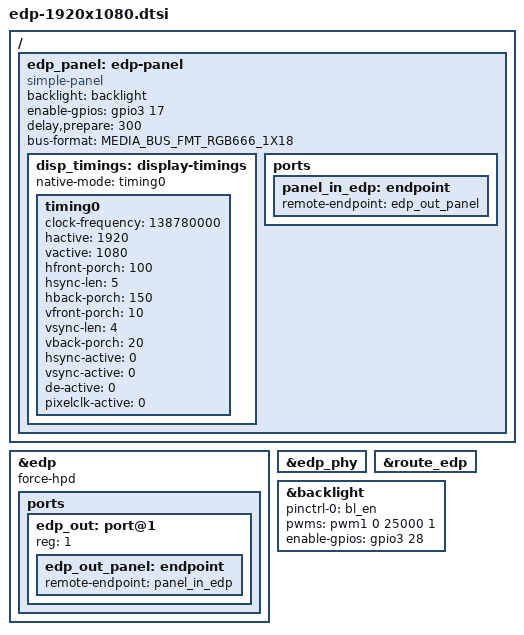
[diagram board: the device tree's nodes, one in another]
/ {
	edp_panel: edp-panel {
		compatible = "simple-panel";
		backlight = <&backlight>;
		enable-gpios = <&gpio3 17 GPIO_ACTIVE_HIGH>;//GPIO0_C2
		delay,prepare = <300>;
		bus-format = <MEDIA_BUS_FMT_RGB666_1X18>;
		disp_timings: display-timings {
			native-mode = <&timing0>;
			timing0: timing0 {
				clock-frequency = <138780000>;
				hactive = <1920>;
				vactive = <1080>;
				hfront-porch = <100>;
				hsync-len = <5>;
				hback-porch = <150>;
				vfront-porch = <10>;
				vsync-len = <4>;
				vback-porch = <20>;
				hsync-active = <0>;
				vsync-active = <0>;
				de-active = <0>;
				pixelclk-active = <0>;
			};
		};
		ports {
			panel_in_edp: endpoint {
				remote-endpoint = <&edp_out_panel>;
			};
		};
	};
};

&edp {
	force-hpd;
	status = "okay";
	ports {
		edp_out: port@1 {
			reg = <1>;
			#address-cells = <1>;
			#size-cells = <0>;
			edp_out_panel: endpoint {
				remote-endpoint = <&panel_in_edp>;
			};
		};
	};
};

&edp_phy {
	status = "okay";
};

&route_edp {
	status = "okay";
};

&backlight {
        status = "okay";
        pinctrl-names = "default";
        pinctrl-0 = <&bl_en>;
        pwms = <&pwm1 0 25000 1>;
        enable-gpios = <&gpio3 28 GPIO_ACTIVE_HIGH>;
};
